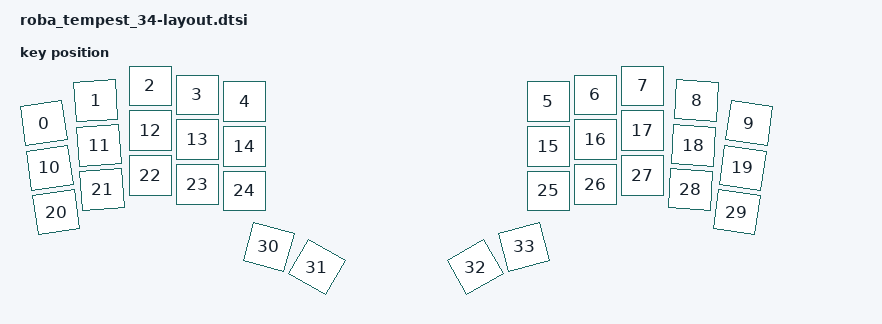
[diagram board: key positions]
// Generated by scripts/generate_layout.py; dimensions normalized to 19 mm.
/ {
    rt34_layout: rt34_layout {
        compatible = "zmk,physical-layout";
        display-name = "Tempest MID + FAR / 34 keys";
        transform = <&rt34_transform>;
        kscan = <&rt34_scan>;
        keys =
              <&key_physical_attrs 92 87 0 75 (-800) 46 119> // 0: left matrix_pinky_top
            , <&key_physical_attrs 92 87 104 30 (-400) 151 73> // 1: left matrix_ring_top
            , <&key_physical_attrs 92 87 213 0 0 259 43> // 2: left matrix_middle_top
            , <&key_physical_attrs 92 87 307 18 0 353 61> // 3: left matrix_index_top
            , <&key_physical_attrs 92 87 402 31 0 448 75> // 4: left matrix_inner_top
            , <&key_physical_attrs 92 87 1009 31 0 1055 75> // 5: right matrix_inner_top
            , <&key_physical_attrs 92 87 1103 18 0 1149 61> // 6: right matrix_index_top
            , <&key_physical_attrs 92 87 1198 0 0 1244 43> // 7: right matrix_middle_top
            , <&key_physical_attrs 92 87 1306 30 400 1352 73> // 8: right matrix_ring_top
            , <&key_physical_attrs 92 87 1411 75 800 1457 119> // 9: right matrix_pinky_top
            , <&key_physical_attrs 92 87 12 164 (-800) 59 207> // 10: left matrix_pinky_home
            , <&key_physical_attrs 92 87 111 119 (-400) 157 162> // 11: left matrix_ring_home
            , <&key_physical_attrs 92 87 213 89 0 259 133> // 12: left matrix_middle_home
            , <&key_physical_attrs 92 87 307 107 0 353 151> // 13: left matrix_index_home
            , <&key_physical_attrs 92 87 402 121 0 448 164> // 14: left matrix_inner_home
            , <&key_physical_attrs 92 87 1009 121 0 1055 164> // 15: right matrix_inner_home
            , <&key_physical_attrs 92 87 1103 107 0 1149 151> // 16: right matrix_index_home
            , <&key_physical_attrs 92 87 1198 89 0 1244 133> // 17: right matrix_middle_home
            , <&key_physical_attrs 92 87 1300 119 400 1346 162> // 18: right matrix_ring_home
            , <&key_physical_attrs 92 87 1398 164 800 1444 207> // 19: right matrix_pinky_home
            , <&key_physical_attrs 92 87 25 253 (-800) 71 296> // 20: left matrix_pinky_bottom
            , <&key_physical_attrs 92 87 117 208 (-400) 163 251> // 21: left matrix_ring_bottom
            , <&key_physical_attrs 92 87 213 179 0 259 222> // 22: left matrix_middle_bottom
            , <&key_physical_attrs 92 87 307 197 0 353 240> // 23: left matrix_index_bottom
            , <&key_physical_attrs 92 87 402 210 0 448 254> // 24: left matrix_inner_bottom
            , <&key_physical_attrs 92 87 1009 210 0 1055 254> // 25: right matrix_inner_bottom
            , <&key_physical_attrs 92 87 1103 197 0 1149 240> // 26: right matrix_index_bottom
            , <&key_physical_attrs 92 87 1198 179 0 1244 222> // 27: right matrix_middle_bottom
            , <&key_physical_attrs 92 87 1294 208 400 1340 251> // 28: right matrix_ring_bottom
            , <&key_physical_attrs 92 87 1386 253 800 1432 296> // 29: right matrix_pinky_bottom
            , <&key_physical_attrs 92 87 450 322 1500 496 366> // 30: left thumb_mid
            , <&key_physical_attrs 92 87 547 363 3000 593 406> // 31: left thumb_far
            , <&key_physical_attrs 92 87 863 363 (-3000) 909 406> // 32: right thumb_far
            , <&key_physical_attrs 92 87 961 322 (-1500) 1007 366> // 33: right thumb_mid
            ;
    };
};
